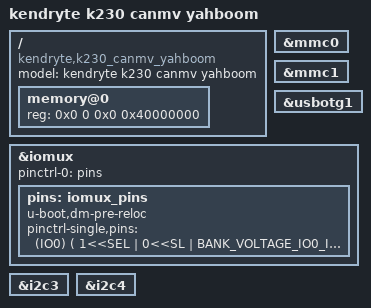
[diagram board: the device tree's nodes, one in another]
/dts-v1/;
#include <dt-bindings/pinctrl/k230_evb.h>

#define BANK_VOLTAGE_IO0_IO1	 K230_MSC_1V8  // FIXED
#define BANK_VOLTAGE_IO2_IO13	 K230_MSC_3V3
#define BANK_VOLTAGE_IO14_IO25	 K230_MSC_3V3
#define BANK_VOLTAGE_IO26_IO37	 K230_MSC_3V3
#define BANK_VOLTAGE_IO38_IO49	 K230_MSC_3V3
#define BANK_VOLTAGE_IO50_IO61	 K230_MSC_3V3
#define BANK_VOLTAGE_IO62_IO63	 K230_MSC_1V8
#include "k230.dtsi"

/ {
	model = "kendryte k230 canmv yahboom";
	compatible = "kendryte,k230_canmv_yahboom";

	memory@0 {
		device_type = "memory";
		reg = <
				0x0 0 0x0 0x40000000
			  >;
	};
};

&mmc0 {
	status = "okay";
};
&mmc1 {
	status = "okay";
};
&usbotg1 {
	status = "okay";
};

&iomux {
	pinctrl-names = "default";
	pinctrl-0 = <&pins>;

	pins: iomux_pins {
		u-boot,dm-pre-reloc;
		pinctrl-single,pins = <

		//BOOT0~1
		(IO0) ( 1<<SEL | 0<<SL | BANK_VOLTAGE_IO0_IO1 <<MSC | 0<<IE | 1<<OE | 1<<PU | 0<<PD | 2<<DS | 0<<ST )
		(IO1) ( 1<<SEL | 0<<SL | BANK_VOLTAGE_IO0_IO1 <<MSC | 0<<IE | 1<<OE | 1<<PU | 0<<PD | 2<<DS | 0<<ST )

		(IO2) ( 0<<SEL | 0<<SL | BANK_VOLTAGE_IO2_IO13 <<MSC | 1<<IE | 1<<OE | 0<<PU | 0<<PD | 7<<DS | 1<<ST )
		(IO3) ( 0<<SEL | 0<<SL | BANK_VOLTAGE_IO2_IO13 <<MSC | 1<<IE | 1<<OE | 0<<PU | 0<<PD | 7<<DS | 1<<ST )
		(IO4) ( 0<<SEL | 0<<SL | BANK_VOLTAGE_IO2_IO13 <<MSC | 1<<IE | 1<<OE | 0<<PU | 0<<PD | 7<<DS | 1<<ST )
		(IO5) ( 0<<SEL | 0<<SL | BANK_VOLTAGE_IO2_IO13 <<MSC | 1<<IE | 1<<OE | 0<<PU | 0<<PD | 7<<DS | 1<<ST )
		(IO6) ( 0<<SEL | 0<<SL | BANK_VOLTAGE_IO2_IO13 <<MSC | 1<<IE | 1<<OE | 0<<PU | 0<<PD | 7<<DS | 1<<ST )
		// CAM2_I2C4_SCL
		(IO7) ( 2<<SEL | 0<<SL | BANK_VOLTAGE_IO2_IO13 <<MSC | 1<<IE | 1<<OE | 1<<PU | 0<<PD | 7<<DS | 1<<ST )
		// CAM2_I2C4_SDA
		(IO8) ( 2<<SEL | 0<<SL | BANK_VOLTAGE_IO2_IO13 <<MSC | 1<<IE | 1<<OE | 1<<PU | 0<<PD | 7<<DS | 1<<ST )
		//UART1_TX
		(IO9) ( 2<<SEL | 0<<SL | BANK_VOLTAGE_IO2_IO13 <<MSC | 0<<IE | 1<<OE | 0<<PU | 0<<PD | 7<<DS | 1<<ST )
		//UART1_RX
		(IO10) ( 2<<SEL | 0<<SL | BANK_VOLTAGE_IO2_IO13 <<MSC | 1<<IE | 0<<OE | 0<<PU | 0<<PD | 7<<DS | 1<<ST )
		(IO11) ( 0<<SEL | 0<<SL | BANK_VOLTAGE_IO2_IO13 <<MSC | 1<<IE | 1<<OE | 0<<PU | 0<<PD | 7<<DS | 1<<ST )
		(IO12) ( 0<<SEL | 0<<SL | BANK_VOLTAGE_IO2_IO13 <<MSC | 1<<IE | 1<<OE | 0<<PU | 0<<PD | 7<<DS | 1<<ST )
		(IO13) ( 0<<SEL | 0<<SL | BANK_VOLTAGE_IO2_IO13 <<MSC | 1<<IE | 1<<OE | 0<<PU | 0<<PD | 7<<DS | 1<<ST )

		(IO14) ( 0<<SEL | 0<<SL | BANK_VOLTAGE_IO14_IO25 <<MSC | 1<<IE | 1<<OE | 0<<PU | 0<<PD | 7<<DS | 1<<ST )
		(IO15) ( 0<<SEL | 0<<SL | BANK_VOLTAGE_IO14_IO25 <<MSC | 1<<IE | 1<<OE | 0<<PU | 0<<PD | 7<<DS | 1<<ST )
		//RGB/LCD data
		(IO16) ( 0<<SEL | 0<<SL | BANK_VOLTAGE_IO14_IO25 <<MSC | 1<<IE | 1<<OE | 0<<PU | 0<<PD | 7<<DS | 1<<ST )
		(IO17) ( 0<<SEL | 0<<SL | BANK_VOLTAGE_IO14_IO25 <<MSC | 1<<IE | 1<<OE | 0<<PU | 0<<PD | 7<<DS | 1<<ST )
		(IO18) ( 0<<SEL | 0<<SL | BANK_VOLTAGE_IO14_IO25 <<MSC | 1<<IE | 1<<OE | 0<<PU | 0<<PD | 7<<DS | 1<<ST )
		(IO19) ( 0<<SEL | 0<<SL | BANK_VOLTAGE_IO14_IO25 <<MSC | 1<<IE | 1<<OE | 0<<PU | 0<<PD | 7<<DS | 1<<ST )
		(IO20) ( 0<<SEL | 0<<SL | BANK_VOLTAGE_IO14_IO25 <<MSC | 1<<IE | 1<<OE | 0<<PU | 0<<PD | 7<<DS | 1<<ST )
		(IO21) ( 0<<SEL | 0<<SL | BANK_VOLTAGE_IO14_IO25 <<MSC | 1<<IE | 1<<OE | 0<<PU | 0<<PD | 7<<DS | 1<<ST )
		//LCD_RST
		(IO22) ( 0<<SEL | 0<<SL | BANK_VOLTAGE_IO14_IO25 <<MSC | 1<<IE | 1<<OE | 0<<PU | 0<<PD | 15<<DS | 1<<ST )
		//TP_INT
		(IO23) ( 0<<SEL | 0<<SL | BANK_VOLTAGE_IO14_IO25 <<MSC | 1<<IE | 0<<OE | 1<<PU | 0<<PD | 15<<DS | 1<<ST )
		//TP_RST
		(IO24) ( 0<<SEL | 0<<SL | BANK_VOLTAGE_IO14_IO25 <<MSC | 1<<IE | 1<<OE | 0<<PU | 0<<PD | 15<<DS | 1<<ST )
		//LCD_EN
		(IO25) ( 0<<SEL | 0<<SL | BANK_VOLTAGE_IO14_IO25 <<MSC | 1<<IE | 1<<OE | 0<<PU | 0<<PD | 7<<DS | 1<<ST )

		//GPIO_26
		(IO26) ( 0<<SEL | 0<<SL | BANK_VOLTAGE_IO26_IO37 <<MSC | 1<<IE | 1<<OE | 0<<PU | 0<<PD | 8<<DS | 0<<ST )
		(IO27) ( 0<<SEL | 0<<SL | BANK_VOLTAGE_IO26_IO37 <<MSC | 1<<IE | 1<<OE | 0<<PU | 0<<PD | 7<<DS | 1<<ST )
		(IO28) ( 0<<SEL | 0<<SL | BANK_VOLTAGE_IO26_IO37 <<MSC | 1<<IE | 1<<OE | 0<<PU | 0<<PD | 7<<DS | 1<<ST )
		(IO29) ( 0<<SEL | 0<<SL | BANK_VOLTAGE_IO26_IO37 <<MSC | 1<<IE | 1<<OE | 0<<PU | 0<<PD | 7<<DS | 1<<ST )
		(IO30) ( 0<<SEL | 0<<SL | BANK_VOLTAGE_IO26_IO37 <<MSC | 1<<IE | 1<<OE | 0<<PU | 0<<PD | 7<<DS | 1<<ST )
		(IO31) ( 0<<SEL | 0<<SL | BANK_VOLTAGE_IO26_IO37 <<MSC | 1<<IE | 1<<OE | 0<<PU | 0<<PD | 7<<DS | 1<<ST )
		//GPIO_32~35
		(IO32) ( 0<<SEL | 0<<SL | BANK_VOLTAGE_IO26_IO37 <<MSC | 1<<IE | 1<<OE | 0<<PU | 0<<PD | 8<<DS | 0<<ST )
		(IO33) ( 0<<SEL | 0<<SL | BANK_VOLTAGE_IO26_IO37 <<MSC | 1<<IE | 1<<OE | 0<<PU | 0<<PD | 8<<DS | 0<<ST )
		(IO34) ( 0<<SEL | 0<<SL | BANK_VOLTAGE_IO26_IO37 <<MSC | 1<<IE | 1<<OE | 0<<PU | 0<<PD | 8<<DS | 0<<ST )
		(IO35) ( 0<<SEL | 0<<SL | BANK_VOLTAGE_IO26_IO37 <<MSC | 1<<IE | 1<<OE | 0<<PU | 0<<PD | 8<<DS | 0<<ST )
		(IO36) ( 0<<SEL | 0<<SL | BANK_VOLTAGE_IO26_IO37 <<MSC | 1<<IE | 1<<OE | 0<<PU | 0<<PD | 7<<DS | 1<<ST )
		(IO37) ( 0<<SEL | 0<<SL | BANK_VOLTAGE_IO26_IO37 <<MSC | 1<<IE | 1<<OE | 0<<PU | 0<<PD | 7<<DS | 1<<ST )

		//UART0_TX
		(IO38) ( 1<<SEL | 0<<SL | BANK_VOLTAGE_IO38_IO49 <<MSC | 0<<IE | 1<<OE | 0<<PU | 0<<PD | 7<<DS | 1<<ST )
		//UART0_RX
		(IO39) ( 1<<SEL | 0<<SL | BANK_VOLTAGE_IO38_IO49 <<MSC | 1<<IE | 0<<OE | 0<<PU | 0<<PD | 7<<DS | 1<<ST )
		(IO40) ( 0<<SEL | 0<<SL | BANK_VOLTAGE_IO38_IO49 <<MSC | 1<<IE | 1<<OE | 0<<PU | 0<<PD | 7<<DS | 1<<ST )
		(IO41) ( 0<<SEL | 0<<SL | BANK_VOLTAGE_IO38_IO49 <<MSC | 1<<IE | 1<<OE | 0<<PU | 0<<PD | 7<<DS | 1<<ST )
		//GPIO_42~43
		(IO42) ( 0<<SEL | 0<<SL | BANK_VOLTAGE_IO38_IO49 <<MSC | 1<<IE | 1<<OE | 0<<PU | 0<<PD | 8<<DS | 0<<ST )
		(IO43) ( 0<<SEL | 0<<SL | BANK_VOLTAGE_IO38_IO49 <<MSC | 1<<IE | 1<<OE | 0<<PU | 0<<PD | 8<<DS | 0<<ST )
		//TP_SCL
		(IO44) ( 2<<SEL | 0<<SL | BANK_VOLTAGE_IO38_IO49 <<MSC | 1<<IE | 1<<OE | 1<<PU | 0<<PD | 7<<DS | 1<<ST )
		//TP_SDA
		(IO45) ( 2<<SEL | 0<<SL | BANK_VOLTAGE_IO38_IO49 <<MSC | 1<<IE | 1<<OE | 1<<PU | 0<<PD | 7<<DS | 1<<ST )
		(IO46) ( 0<<SEL | 0<<SL | BANK_VOLTAGE_IO38_IO49 <<MSC | 1<<IE | 1<<OE | 0<<PU | 0<<PD | 7<<DS | 1<<ST )
		(IO47) ( 0<<SEL | 0<<SL | BANK_VOLTAGE_IO38_IO49 <<MSC | 1<<IE | 1<<OE | 0<<PU | 0<<PD | 7<<DS | 1<<ST )
		//Voice_EN
		(IO48) ( 0<<SEL | 0<<SL | BANK_VOLTAGE_IO38_IO49 <<MSC | 1<<IE | 1<<OE | 0<<PU | 0<<PD | 7<<DS | 1<<ST )
		(IO49) ( 0<<SEL | 0<<SL | BANK_VOLTAGE_IO38_IO49 <<MSC | 1<<IE | 1<<OE | 0<<PU | 0<<PD | 7<<DS | 1<<ST )

		(IO50) ( 0<<SEL | 0<<SL | BANK_VOLTAGE_IO50_IO61 <<MSC | 1<<IE | 1<<OE | 0<<PU | 0<<PD | 7<<DS | 1<<ST )
		(IO51) ( 0<<SEL | 0<<SL | BANK_VOLTAGE_IO50_IO61 <<MSC | 1<<IE | 1<<OE | 0<<PU | 0<<PD | 7<<DS | 1<<ST )
		(IO52) ( 0<<SEL | 0<<SL | BANK_VOLTAGE_IO50_IO61 <<MSC | 1<<IE | 1<<OE | 0<<PU | 0<<PD | 7<<DS | 1<<ST )
		//Buzzer
		(IO53) ( 2<<SEL | 0<<SL | BANK_VOLTAGE_IO50_IO61 <<MSC | 0<<IE | 1<<OE | 0<<PU | 0<<PD | 7<<DS | 1<<ST )
		//TFCARD_CMD
		(IO54) ( 2<<SEL | 0<<SL | BANK_VOLTAGE_IO50_IO61 <<MSC | 1<<IE | 1<<OE | 1<<PU | 0<<PD | 7<<DS | 1<<ST )
		//TFCARD_CLK
		(IO55) ( 2<<SEL | 0<<SL | BANK_VOLTAGE_IO50_IO61 <<MSC | 0<<IE | 1<<OE | 0<<PU | 0<<PD | 7<<DS | 1<<ST )
		//TFCARD_D0
		(IO56) ( 2<<SEL | 0<<SL | BANK_VOLTAGE_IO50_IO61 <<MSC | 1<<IE | 1<<OE | 1<<PU | 0<<PD | 7<<DS | 1<<ST )
		//TFCARD_D1
		(IO57) ( 2<<SEL | 0<<SL | BANK_VOLTAGE_IO50_IO61 <<MSC | 1<<IE | 1<<OE | 1<<PU | 0<<PD | 7<<DS | 1<<ST )
		//TFCARD_D2
		(IO58) ( 2<<SEL | 0<<SL | BANK_VOLTAGE_IO50_IO61 <<MSC | 1<<IE | 1<<OE | 1<<PU | 0<<PD | 7<<DS | 1<<ST )
		//TFCARD_D3
		(IO59) ( 2<<SEL | 0<<SL | BANK_VOLTAGE_IO50_IO61 <<MSC | 1<<IE | 1<<OE | 1<<PU | 0<<PD | 7<<DS | 1<<ST )
		(IO60) ( 0<<SEL | 0<<SL | BANK_VOLTAGE_IO50_IO61 <<MSC | 1<<IE | 1<<OE | 0<<PU | 0<<PD | 15<<DS | 1<<ST )
		//KEY1 (GPIO61), active low
		(IO61) ( 0<<SEL | 0<<SL | BANK_VOLTAGE_IO50_IO61 <<MSC | 1<<IE | 0<<OE | 1<<PU | 0<<PD | 7<<DS | 1<<ST )

		// CAM2_RST
		(IO62) ( 0<<SEL | 0<<SL | BANK_VOLTAGE_IO62_IO63 <<MSC | 0<<IE | 1<<OE | 0<<PU | 1<<PD | 4<<DS | 1<<ST )
		// CAM2_MCLK
		(IO63) ( 1<<SEL | 0<<SL | BANK_VOLTAGE_IO62_IO63 <<MSC | 0<<IE | 1<<OE | 0<<PU | 1<<PD | 4<<DS | 1<<ST )
		>;
	};
};

&i2c3 {
	status = "okay";
};

&i2c4 {
	status = "okay";
};
